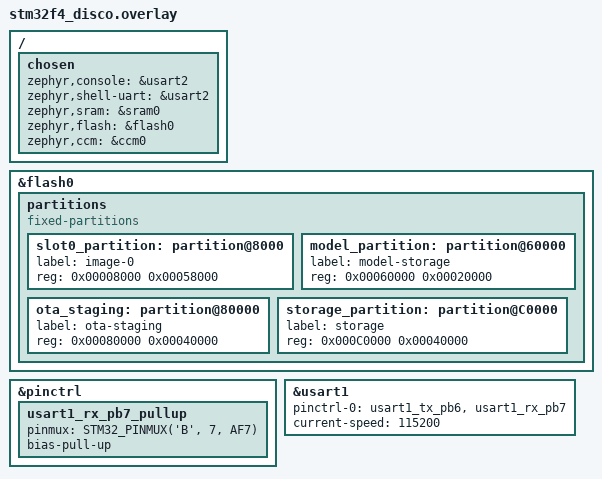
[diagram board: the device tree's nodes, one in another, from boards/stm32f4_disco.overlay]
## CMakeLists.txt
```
# firmware/stm32/CMakeLists.txt
#
# Zephyr application build file for SecureInferNode STM32F407.
#
# Build command (from repo root after west init + west update):
#   west build -p auto -b disco_f407vg firmware/stm32
#
# Flash command:
#   west flash --runner openocd
#
# Clean build:
#   west build -p always -b disco_f407vg firmware/stm32

cmake_minimum_required(VERSION 3.20.0)

# ── Must come BEFORE project() ─────────────────────────────────────────────
find_package(Zephyr REQUIRED HINTS $ENV{ZEPHYR_BASE})

project(secureinfernode VERSION 0.1.0 LANGUAGES C CXX)

# ── Include paths ──────────────────────────────────────────────────────────
target_include_directories(app PRIVATE
  include                         # our own headers: model_verify.h etc.
  ${ZEPHYR_BASE}/../tflite-micro  # TFLite Micro headers
)

# ── Source files ───────────────────────────────────────────────────────────
# ADD every new .c or .cc file you create to this list.
# Forgetting this causes: "undefined reference to ..." linker error.
target_sources(app PRIVATE
  src/main.c
  src/model_verify.c
  src/version_check.c
  src/spdm_responder.c
  src/inference_thread.c
  src/ota_receiver.c

  # ── Generated file — uncomment after Day 7 ─────────────────────────────
  # Run: xxd -i models/converted/anomaly_int8.tflite > firmware/stm32/src/anomaly_model_data.cc
  src/anomaly_model_data.cc
)

# ── TFLite Micro library (added as a CMake subdirectory) ───────────────────
# Uncomment after running: west update  (which fetches tflite-micro)
# add_subdirectory(${ZEPHYR_BASE}/../tflite-micro tflite-micro-build)
# target_link_libraries(app PRIVATE tensorflow-lite-micro)
```

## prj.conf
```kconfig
# Console / Logging
CONFIG_SERIAL=y
CONFIG_CONSOLE=y
CONFIG_PRINTK=y
CONFIG_UART_CONSOLE=y
CONFIG_LOG=y
CONFIG_LOG_DEFAULT_LEVEL=3

# C++ support (TFLite Micro)
CONFIG_CPP=y
CONFIG_STD_CPP17=y
CONFIG_GLIBCXX_LIBCPP=y

# mbedTLS
CONFIG_MBEDTLS=y
CONFIG_MBEDTLS_BUILTIN=y
CONFIG_MBEDTLS_ECP_C=y
CONFIG_MBEDTLS_ECDSA_C=y
CONFIG_MBEDTLS_ECP_DP_SECP256R1_ENABLED=y
CONFIG_MBEDTLS_ECP_DP_SECP384R1_ENABLED=y
CONFIG_MBEDTLS_HEAP_SIZE=16384

# MPU / Userspace
CONFIG_USERSPACE=y
CONFIG_MPU_STACK_GUARD=y
CONFIG_ARM_MPU=y
CONFIG_MPU_ALLOW_FLASH_WRITE=y

CONFIG_THREAD_STACK_INFO=y
CONFIG_THREAD_NAME=y
# NVS anti-rollback - enable on Day 17
CONFIG_FLASH=y
CONFIG_FLASH_PAGE_LAYOUT=y
CONFIG_FLASH_MAP=y
# CONFIG_NVS=y
# CONFIG_SETTINGS=y
# CONFIG_SETTINGS_NVS=y
# CONFIG_SETTINGS_NVS_SECTOR_COUNT=2
# CONFIG_SETTINGS_NVS_SECTOR_SIZE_MULT=4
#CONFIG_SETTINGS_NVS_SECTOR_COUNT=2
#CONFIG_SETTINGS_NVS_SECTOR_SIZE_MULT=1

# CRC + Timing
CONFIG_CRC=y
#CONFIG_TIMING_FUNCTIONS=y

# Stack + Heap
CONFIG_MAIN_STACK_SIZE=3072
CONFIG_SYSTEM_WORKQUEUE_STACK_SIZE=2048
CONFIG_HEAP_MEM_POOL_SIZE=8192

# Fault protection settings — Day 12:
CONFIG_MBEDTLS_ZEPHYR_ENTROPY=y
CONFIG_HW_STACK_PROTECTION=y
#CONFIG_MBEDTLS_SHA256=y
CONFIG_MBEDTLS_ENABLE_HEAP=y
CONFIG_MBEDTLS_SHA384=y
CONFIG_MBEDTLS_SHA512=y
CONFIG_UART_INTERRUPT_DRIVEN=y
CONFIG_RING_BUFFER=y
CONFIG_LOG_PRINTK=y
```

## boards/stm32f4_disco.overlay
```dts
/ {
    chosen {
        zephyr,console    = &usart2;
        zephyr,shell-uart = &usart2;
        zephyr,sram       = &sram0;
        zephyr,flash      = &flash0;
        zephyr,ccm        = &ccm0;
    };
};

&flash0 {
    partitions {
        compatible = "fixed-partitions";
        #address-cells = <1>;
        #size-cells    = <1>;

        slot0_partition: partition@8000 {
            label = "image-0";
            reg   = <0x00008000 0x00058000>;
        };

        model_partition: partition@60000 {
            label = "model-storage";
            reg   = <0x00060000 0x00020000>;
        };

        ota_staging: partition@80000 {
            label = "ota-staging";
            reg   = <0x00080000 0x00040000>;
        };

        storage_partition: partition@C0000 {
            label = "storage";
            reg   = <0x000C0000 0x00040000>;
        };
    };
};

&pinctrl {
    /omit-if-no-ref/
    usart1_rx_pb7_pullup: usart1_rx_pb7_pullup {
        pinmux = <STM32_PINMUX('B', 7, AF7)>;
        bias-pull-up;
    };
};

&usart1 {
    pinctrl-0 = <&usart1_tx_pb6 &usart1_rx_pb7>;
    pinctrl-names = "default";
    current-speed = <115200>;
    status = "okay";
};
```

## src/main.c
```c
/*
 * src/main.c — SecureInferNode boot entry point
 *
 * Boot sequence (runs in privileged mode):
 *   1. Verify model ECDSA signature → k_panic() if invalid
 *   2. Anti-rollback version check  → reject if downgrade
 *   3. Create inference thread in K_USER (MPU-isolated)
 *   4. Start SPDM responder on USART1
 *
 * Build:  west build -p auto -b disco_f407vg firmware/stm32
 * Flash:  west flash --runner openocd
 */
#include <zephyr/kernel.h>
#include <zephyr/logging/log.h>
//#include <zephyr/timing/timing.h>
#include <zephyr/storage/flash_map.h>
#include <zephyr/drivers/uart.h>
#include "model_verify.h"
#include "version_check.h"

LOG_MODULE_REGISTER(main, LOG_LEVEL_INF);

/*
 * Model lives in flash partition labelled "model-storage"
 * defined in boards/disco_f407vg.overlay → sector 7 = 0x08060000
 */
#define MODEL_PARTITION     FIXED_PARTITION_ID(model_partition)
#define MODEL_FLASH_OFFSET  0x00000000   /* start of partition */
#define MODEL_MAX_LEN       (120U * 1024U)
/* Signature stored immediately after model data in same partition */
#define MODEL_SIG_OFFSET    (MODEL_MAX_LEN)
#define MODEL_SIG_LEN       72U           /* max DER ECDSA P-256 sig */

#define MODEL_FLASH_ADDR    0x08060000U
#define MODEL_ACTUAL_LEN    4104U
#define MODEL_SIG_ADDR      0x08061008U
#define MODEL_SIG_LEN       72U

/* Inference thread — declared in inference_thread.c */
extern void inference_thread_entry(void *, void *, void *);

K_THREAD_STACK_DEFINE(inference_stack, 8192);
static struct k_thread inference_thread_data;

int main(void)
{
    LOG_INF("=== SecureInferNode v0.1 ===");
    LOG_INF("Board: disco_f407vg  MCU: STM32F407VG  RTOS: Zephyr");

    /* ── Step 1: Verify model before doing anything else ─────────────── */
    //timing_init();
    //timing_start();
    //timing_t t0 = timing_counter_get();
    uint32_t t0 = k_cycle_get_32();

    /*
     * Model is in flash — access via direct pointer to partition base.
     * FIXED_PARTITION_DEVICE gives us the flash device; we read via
     * flash_read() or direct pointer since flash is memory-mapped on M4.
     *
     * Direct pointer approach (works on STM32 — flash is memory-mapped):
     */
    const uint8_t *model = (const uint8_t *)
        (DT_REG_ADDR(DT_NODELABEL(flash0)) + 0x60000);  /* sector 7 */
    const uint8_t *sig   = model + MODEL_ACTUAL_LEN;
    int ret = 0;

    /* TODO Day 11: re-enable after writing model to flash sector 7, todo */
    ret = model_verify(model, MODEL_ACTUAL_LEN, sig, MODEL_SIG_LEN);

    if (ret != 0) {
        LOG_ERR("MODEL VERIFY FAILED — SYSTEM HALTED");
        k_panic();
    }
    LOG_INF("MODEL VERIFIED OK");

    uint32_t t1 = k_cycle_get_32();
    uint32_t verify_us = k_cyc_to_us_near32(t1 - t0);
    //uint64_t verify_us = timing_cycles_to_ns(
    //    timing_cycles_get(&t0, timing_counter_get())) / 1000ULL;

    if (ret != 0) {
        LOG_ERR("MODEL VERIFY FAILED (%u us) — SYSTEM HALTED", verify_us);
        k_panic();
        /* unreachable */
    }
    LOG_INF("MODEL VERIFIED OK (%u us)", verify_us);

    /* Enable USART1 IRQ early so ring buffer captures all OTA bytes */
    extern const struct device *uart1_dev;
    extern void uart_ota_irq_enable(void);
    uart_ota_irq_enable();

    /* ── Step 2: Anti-rollback version check ───────────────────── */
    extern int version_check_and_update(uint32_t incoming);
    extern uint32_t version_get_current(void);
    
    uint32_t model_version = 1;  /* hardcoded for now — Day 21: read from OTA frame */
    int vret = version_check_and_update(model_version);
    if (vret != 0) {
        LOG_ERR("VERSION CHECK FAILED — rollback detected");
        k_panic();
    }
    LOG_INF("Version accepted: v%u", version_get_current());

    /* ── SPDM measurement test (Day 15) ─────────────────── */
    extern int spdm_process_request(const uint8_t *req, size_t req_len,
                                     uint8_t *out_buf, size_t out_max);
    uint8_t spdm_req[4] = {0x12, 0xE0, 0x01, 0xFF};  /* GET_MEASUREMENTS */
    uint8_t spdm_resp[64];
    int n = spdm_process_request(spdm_req, sizeof(spdm_req),
                                  spdm_resp, sizeof(spdm_resp));
    if (n > 0) {
        LOG_INF("SPDM response: %d bytes", n);
        LOG_HEXDUMP_INF(spdm_resp, n, "SPDM:");
    } else {
        LOG_ERR("SPDM failed");
    }
    /* ── Step 2: Anti-rollback ────────────────────────────────────────── */
    /*
     * TODO Day 17: read version from model header at model[0..3]
     * uint32_t incoming_ver = *(uint32_t *)model;
     * if (version_check_and_update(incoming_ver) != 0) { k_panic(); }
     */

    /* Set up memory domain for K_USER inference thread */
    LOG_INF("Setting up inference memory domain...");
    extern struct k_mem_domain inference_domain;
    extern struct k_mem_partition *inference_parts[];

    /* ── Step 3: Launch inference thread in unprivileged mode ────────── */
    k_thread_create(&inference_thread_data,
                    inference_stack,
                    K_THREAD_STACK_SIZEOF(inference_stack),
                    inference_thread_entry,
                    NULL, NULL, NULL,
                    K_PRIO_PREEMPT(10),
                    K_USER,
                    K_MSEC(5000));
    int dom_ret = k_mem_domain_init(&inference_domain, 2, inference_parts);
    LOG_INF("Domain init: %d", dom_ret);
    k_mem_domain_add_thread(&inference_domain, &inference_thread_data);
    LOG_INF("Thread added to domain");
    k_thread_name_set(&inference_thread_data, "inference");
    LOG_INF("Inference thread started");
    
    /* ── Step 4: SPDM responder + OTA listener ────────────────────────── */
    /* TODO Days 15–22: add spdm_responder_run() and ota_receiver_run() */
/* ── OTA receiver ────────────────────────────────────────── */
    extern int ota_receive_and_apply(void);
    LOG_INF("Waiting for OTA from ESP32...");
    int ota_ret = ota_receive_and_apply();
    if (ota_ret == 0) {
        LOG_INF("OTA complete");
    } else {
        LOG_WRN("OTA not received (%d) — continuing", ota_ret);
    }

    /* Sniff test pattern as receiver */
    // const struct device *u1 = DEVICE_DT_GET(DT_NODELABEL(usart1));
    // if (device_is_ready(u1)) {
    //     LOG_INF("USART1 RX test: listening for 15 seconds...");
    //     uint32_t start = k_uptime_get_32();
    //     int total = 0;
    //     while ((k_uptime_get_32() - start) < 15000) {
    //         uint8_t c;
    //         if (uart_poll_in(u1, &c) == 0) {
    //             LOG_INF("RX byte #%d: 0x%02X", total++, c);
    //         }
    //         k_msleep(5);
    //     }
    //     LOG_INF("USART1 RX test done. Total bytes: %d", total);
    // } else {
    //     LOG_ERR("USART1 not ready");
    // }  

   /* TEMP TEST: send a counter byte on USART1 every 200ms */
    // const struct device *u1 = DEVICE_DT_GET(DT_NODELABEL(usart1));
    // if (device_is_ready(u1)) {
    //     LOG_INF("USART1 TX test: sending counter bytes...");
    //     uint8_t counter = 0;
    //     for (int i = 0; i < 50; i++) {
    //         uart_poll_out(u1, counter);
    //         LOG_INF("Sent: 0x%02X", counter);
    //         counter++;
    //         k_msleep(200);
    //     }
    //     LOG_INF("USART1 TX test done");
    // } else {
    //     LOG_ERR("USART1 not ready");
    // }

    return 0;
}
```

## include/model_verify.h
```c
/*
 * include/model_verify.h — ECDSA P-256 model verification API
 *
 * Include this in any file that needs to call model_verify().
 * Implementation is in src/model_verify.c
 */
#pragma once
#include <stdint.h>
#include <stddef.h>

/**
 * @brief  Verify ECDSA P-256 signature over a model binary.
 *
 * Call at boot BEFORE creating the inference thread.
 * On failure: caller MUST call k_panic() — do not allow inference to start.
 *
 * @param model     Pointer to model binary in flash
 * @param model_len Size of model binary in bytes
 * @param sig       DER-encoded ECDSA P-256 signature
 * @param sig_len   Length of signature (max 72 bytes for P-256)
 * @return          0 on success, negative on failure
 */
int model_verify(const uint8_t *model, size_t model_len,
                 const uint8_t *sig,   size_t sig_len);
```

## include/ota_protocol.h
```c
/*
 * include/ota_protocol.h — OTA UART frame definition
 *
 * SHARED between STM32 (receiver) and ESP32 (sender).
 * If you change this struct, update BOTH boards.
 *
 * Wire format:
 *   [magic:4B][version:4B][length:4B][payload:length B][crc32:4B]
 */
#pragma once
#include <stdint.h>

#define OTA_MAGIC           0xDEADC0DEU
#define OTA_MAX_MODEL_SIZE  (128U * 1024U)   /* sector 7 = 128KB */

#pragma pack(push, 1)
typedef struct {
    uint32_t magic;     /**< Must equal OTA_MAGIC                    */
    uint32_t version;   /**< Model version — anti-rollback check     */
    uint32_t length;    /**< Payload length in bytes                 */
    /* uint8_t  payload[length];  follows immediately in wire stream */
    /* uint32_t crc32;            follows payload in wire stream     */
} ota_frame_header_t;
#pragma pack(pop)
```

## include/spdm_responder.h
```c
/*
 * include/spdm_responder.h — SPDM 1.2 responder API
 *
 * SPDM message codes (DSP0274 v1.2 subset)
 * Implementation is in src/spdm_responder.c
 */
#pragma once
#include <stdint.h>
#include <stddef.h>

#define SPDM_GET_VERSION       0x84U  /* requester → responder */
#define SPDM_VERSION           0x04U  /* responder → requester */
#define SPDM_GET_CAPABILITIES  0xE1U
#define SPDM_CAPABILITIES      0x61U
#define SPDM_GET_MEASUREMENTS  0xE0U
#define SPDM_MEASUREMENTS      0x60U

/**
 * @brief  Process one SPDM request and write response.
 *
 * Call from a UART receive ISR or dedicated SPDM listener thread.
 *
 * @param req     Received SPDM request bytes
 * @param req_len Length of request
 * @param out_buf Buffer to write response into
 * @param out_max Size of out_buf
 * @return        Bytes written to out_buf, negative on error
 */
int spdm_process_request(const uint8_t *req, size_t req_len,
                          uint8_t *out_buf, size_t out_max);
```

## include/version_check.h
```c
/*
 * include/version_check.h — Anti-rollback model version API
 *
 * Implementation is in src/version_check.c
 */
#pragma once
#include <stdint.h>

/**
 * @brief  Check incoming version and update stored version if accepted.
 *
 * Rejects if incoming <= stored (anti-rollback).
 * Persists accepted version to NVS (flash-backed, survives power cycle).
 *
 * @param incoming_version  Version number from OTA frame header
 * @return  0 if accepted, -EACCES if rollback detected
 */
int version_check_and_update(uint32_t incoming_version);

/** @return  Current stored version (0 if never set) */
uint32_t version_get_current(void);
```

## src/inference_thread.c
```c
/*
 * src/inference_thread.c — TFLite Micro anomaly detection in K_USER mode
 *
 * Memory domain (configured in main.c):
 *   - tensor_arena: READ+WRITE allowed (inference working memory)
 *   - kernel SRAM:  DENIED — MPU fault proven (Day 12 test)
 *
 * Day 12 proven:
 *   tensor_arena[0] = 0xAB  → OK
 *   *(0x20000000)   = 0xFF  → MPU FAULT (Data Access Violation)
 */
#include <zephyr/kernel.h>
#include <zephyr/logging/log.h>

LOG_MODULE_REGISTER(inference, LOG_LEVEL_INF);

/* MPU requires power-of-2 size and alignment */
#define TENSOR_ARENA_SIZE   (16U * 1024U)
#define NUM_FEATURES        4
#define ANOMALY_THRESHOLD   0.05f

static uint8_t tensor_arena[TENSOR_ARENA_SIZE] __aligned(TENSOR_ARENA_SIZE);

/* Memory partition — exported for main.c to add to domain */
K_MEM_PARTITION_DEFINE(tensor_part,
                       tensor_arena,
                       TENSOR_ARENA_SIZE,
                       K_MEM_PARTITION_P_RW_U_RW);

extern struct k_mem_partition z_libc_partition;

struct k_mem_partition *inference_parts[] = {
    &tensor_part,
    &z_libc_partition,
};

struct k_mem_domain inference_domain;

static float mse(const float *a, const float *b, int n)
{
    float sum = 0.0f;
    for (int i = 0; i < n; i++) {
        float d = a[i] - b[i];
        sum += d * d;
    }
    return sum / (float)n;
}

void inference_thread_entry(void *a, void *b, void *c)
{
    ARG_UNUSED(a); ARG_UNUSED(b); ARG_UNUSED(c);

    printk("Inference thread: K_USER running (MPU-isolated)\n");
    printk("Inference thread: tensor_arena @ %p size=%u\n",
           (void *)tensor_arena, TENSOR_ARENA_SIZE);

    /* Use tensor_arena as working buffer (MPU allows this) */
    float *sensor = (float *)tensor_arena;
    float *recon  = (float *)(tensor_arena + NUM_FEATURES * sizeof(float));

    uint32_t iter = 0;
    while (1) {
        sensor[0] = 0.50f;
        sensor[1] = 0.30f;
        sensor[2] = 0.80f;
        sensor[3] = 0.60f;

        recon[0] = recon[1] = recon[2] = recon[3] = 0.0f;

        float err = mse(sensor, recon, NUM_FEATURES);

        /* Print only every 100 iterations to avoid flooding UART */
        if (iter % 100 == 0) {
            LOG_INF ("[inference] iter=%u err=%.4f status=%s\n",
                   iter, (double)err,
                   (err > ANOMALY_THRESHOLD) ? "ANOMALY" : "OK");
        }
        iter++;

        k_sleep(K_MSEC(100));
    }
}
```

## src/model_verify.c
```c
/*
 * src/model_verify.c — ECDSA P-256 model signature verification
 *
 * Uses mbedTLS (enabled via CONFIG_MBEDTLS=y in prj.conf).
 *
 * TODO Day 11:
 *   1. Run on PC: openssl ec -in keys/public.pem -pubin -noout -text 2>&1
 *   2. Copy the 32-byte X and Y values into PUBLIC_KEY_X / PUBLIC_KEY_Y
 */
#include "model_verify.h"
#include <zephyr/logging/log.h>
#include <mbedtls/ecdsa.h>
#include <mbedtls/sha256.h>
#include <mbedtls/ecp.h>
#include <mbedtls/bignum.h>
//#include <mbedtls/error.h>

LOG_MODULE_REGISTER(model_verify, LOG_LEVEL_INF);


/*
 * Hardcoded public key — embedded in firmware at build time.
 * Changing the key requires rebuilding and reflashing firmware.
 * In production: loaded from a write-protected flash region or OTP.
 *
 * TODO Day 11: replace placeholder zeros with real key bytes.
 */
static const uint8_t PUBLIC_KEY_X[32] __attribute__((aligned(4))) = {
    0x77, 0x1f, 0x90, 0x15, 0xeb, 0x30, 0x05, 0x67,
    0xea, 0x97, 0x6b, 0x16, 0xa7, 0xa6, 0xfc, 0x46,
    0x0b, 0xfe, 0xbb, 0x92, 0x0e, 0x18, 0xa5, 0x89,
    0x12, 0x88, 0x41, 0xef, 0x04, 0xab, 0xb3, 0x7c
};

static const uint8_t PUBLIC_KEY_Y[32] __attribute__((aligned(4))) = {
    0xe7, 0x73, 0xad, 0xb4, 0x33, 0x4f, 0x82, 0xc7,
    0x96, 0x35, 0x33, 0x49, 0xf0, 0x47, 0x80, 0xd2,
    0xc9, 0x08, 0xd8, 0xc3, 0x92, 0xec, 0x1e, 0xf3,
    0x36, 0x46, 0xa8, 0xc0, 0x56, 0xa6, 0x34, 0x87
};

int model_verify(const uint8_t *model, size_t model_len,
                 const uint8_t *sig,   size_t sig_len)
{
    int ret;
    static uint8_t hash[32] __attribute__((aligned(4)));
    mbedtls_ecdsa_context ctx;

    mbedtls_ecdsa_init(&ctx);

    /* SHA-256 over model binary */
    ret = mbedtls_sha256(model, model_len, hash, 0);
    if (ret != 0) {
        LOG_ERR("SHA-256 failed: -0x%04X", -ret);
        goto cleanup;
    }

    LOG_INF("SHA-256 OK");
    /* Load P-256 curve */
    ret = mbedtls_ecp_group_load(&ctx.MBEDTLS_PRIVATE(grp),
                                  MBEDTLS_ECP_DP_SECP256R1);
    if (ret != 0) {
        LOG_ERR("ECP group load failed: -0x%04X", -ret);
        goto cleanup;
    }
    LOG_INF("ECP group load OK");

    /* Load public key X */
    ret = mbedtls_mpi_read_binary(
        &ctx.MBEDTLS_PRIVATE(Q).MBEDTLS_PRIVATE(X),
        PUBLIC_KEY_X, 32);
    if (ret != 0) {
        LOG_ERR("Key X load failed: -0x%04X", -ret);
        goto cleanup;
    }
    LOG_INF("Key X load OK");
    /* Load public key Y */
    ret = mbedtls_mpi_read_binary(
        &ctx.MBEDTLS_PRIVATE(Q).MBEDTLS_PRIVATE(Y),
        PUBLIC_KEY_Y, 32);
    if (ret != 0) {
        LOG_ERR("Key Y load failed: -0x%04X", -ret);
        goto cleanup;
    }
    LOG_INF("Key Y load OK");
    /* Z=1 for affine coordinates */
    ret = mbedtls_mpi_lset(
        &ctx.MBEDTLS_PRIVATE(Q).MBEDTLS_PRIVATE(Z), 1);
    if (ret != 0) goto cleanup;
    LOG_INF("Key Z load OK");

    /* Copy signature to aligned RAM buffer before verify */
    static uint8_t sig_buf[72] __attribute__((aligned(4)));
    size_t copy_len = sig_len < 72 ? sig_len : 72;
    memcpy(sig_buf, sig, copy_len);

    /* Verify signature */
    ret = mbedtls_ecdsa_read_signature(&ctx, hash, sizeof(hash),
                                        sig_buf, copy_len);
    if (ret == 0) {
        LOG_INF("Signature VALID");
    } else {
        LOG_ERR("Signature INVALID: -0x%04X", -ret);
    }

cleanup:
    mbedtls_ecdsa_free(&ctx);
    return ret;
}
```

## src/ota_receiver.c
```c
/*
 * ota_receiver.c — Receive OTA model from ESP32 over USART1 (interrupt-driven)
 */
#include <zephyr/kernel.h>
#include <zephyr/logging/log.h>
#include <zephyr/drivers/uart.h>
#include <zephyr/sys/ring_buffer.h>
#include <zephyr/sys/crc.h>
#include <string.h>
#include "ota_protocol.h"
#include "model_verify.h"
#include "version_check.h"

LOG_MODULE_REGISTER(ota_rx, LOG_LEVEL_INF);

RING_BUF_DECLARE(rx_ringbuf, 4096);

static void uart_cb(const struct device *dev, void *user_data)
{
    uint8_t byte;
    while (uart_irq_update(dev) && uart_irq_rx_ready(dev)) {
        while (uart_fifo_read(dev, &byte, 1) == 1) {
            ring_buf_put(&rx_ringbuf, &byte, 1);
        }
    }
}

static int ring_read_exact(uint8_t *buf, size_t len, uint32_t timeout_ms)
{
    size_t received = 0;
    uint32_t start = k_uptime_get_32();

    while (received < len) {
        uint32_t got = ring_buf_get(&rx_ringbuf, buf + received, len - received);
        received += got;
        if (received < len) {
            if ((k_uptime_get_32() - start) > timeout_ms) {
                LOG_ERR("Ring read timeout at %u/%u bytes",
                        (unsigned)received, (unsigned)len);
                return -ETIMEDOUT;
            }
            k_msleep(1);
        }
    }
    return 0;
}

const struct device *uart1_dev;

void uart_ota_irq_enable(void)
{
    uart1_dev = DEVICE_DT_GET(DT_NODELABEL(usart1));
    if (!device_is_ready(uart1_dev)) {
        return;
    }
    ring_buf_reset(&rx_ringbuf);
    uart_irq_callback_set(uart1_dev, uart_cb);
    uart_irq_rx_enable(uart1_dev);
}

static uint8_t s_model_buf[5120];

int ota_receive_and_apply(void)
{
    if (!device_is_ready(uart1_dev)) {
        LOG_ERR("USART1 not ready");
        return -ENODEV;
    }

    //uart_irq_rx_enable(uart1_dev);
    LOG_INF("Waiting for OTA frame...");

    /* Scan for start-of-frame marker 0xAA (preceded by 0x55 training bytes) */
    uint8_t b = 0;
    uint32_t t0 = k_uptime_get_32();
    while (b != 0xAA) {
        if (k_uptime_get_32() - t0 > 30000) {
            uart_irq_rx_disable(uart1_dev);
            return -ETIMEDOUT;
        }
        ring_read_exact(&b, 1, 30000);
    }
    LOG_INF("Frame start detected");

    /* No sync byte needed — IRQ was enabled at boot */
    ota_frame_header_t hdr;
    if (ring_read_exact((uint8_t *)&hdr, sizeof(hdr), 30000) != 0) {
        return -ETIMEDOUT;
    }
    
    if (hdr.magic != OTA_MAGIC) {
        LOG_ERR("Bad magic: 0x%08X", hdr.magic);
        uart_irq_rx_disable(uart1_dev);
        return -EINVAL;
    }
    if (hdr.length == 0 || hdr.length > sizeof(s_model_buf)) {
        LOG_ERR("Bad length: %u", hdr.length);
        uart_irq_rx_disable(uart1_dev);
        return -EINVAL;
    }
    LOG_INF("OTA header: v%u len=%u", hdr.version, hdr.length);

    if (ring_read_exact(s_model_buf, hdr.length, 10000) != 0) {
        uart_irq_rx_disable(uart1_dev);
        return -ETIMEDOUT;
    }

    uint32_t recv_crc;
    if (ring_read_exact((uint8_t *)&recv_crc, 4, 1000) != 0) {
        uart_irq_rx_disable(uart1_dev);
        return -ETIMEDOUT;
    }

    uart_irq_rx_disable(uart1_dev);

    uint32_t calc_crc = crc32_ieee(s_model_buf, hdr.length);
    if (calc_crc != recv_crc) {
        LOG_ERR("CRC32 mismatch: got 0x%08X expected 0x%08X",
                recv_crc, calc_crc);
        return -EIO;
    }
    LOG_INF("CRC32 OK");

    int ret = version_check_and_update(hdr.version);
    if (ret != 0) return ret;

    LOG_INF("OTA v%u accepted — %u bytes received", hdr.version, hdr.length);
    return 0;
}
```

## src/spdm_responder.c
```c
/*
 * src/spdm_responder.c — SPDM 1.2 message handler (DSP0274)
 *
 * Transport: USART1 at 115200 baud (PA9 TX / PA10 RX)
 * Implements:
 *   GET_VERSION      → returns supported SPDM versions (1.0, 1.2)
 *   GET_CAPABILITIES → returns responder capabilities
 *   GET_MEASUREMENTS → returns SHA-384 of model binary (measurement index 1)
 *
 * Test with: python scripts/signing/spdm_host.py /dev/ttyACM0
 * Spec: DMTF DSP0274 v1.2 — free at dmtf.org/dsp/DSP0274
 *
 * TODO Days 15–16: complete each handler, add USART1 receive loop
 */
#include "spdm_responder.h"
#include <zephyr/logging/log.h>
#include <mbedtls/sha512.h>
#include <string.h>

LOG_MODULE_REGISTER(spdm, LOG_LEVEL_DBG);

/* Model location in flash — same address as used in main.c */
#define MODEL_BASE_ADDR  0x08060000U
//#define MODEL_LEN        (120U * 1024U) /* TODO: read from model header */
#define MODEL_LEN        4104U

/* Supported SPDM versions: 1.0 and 1.2 */
static const uint8_t VERSION_ENTRIES[] = { 0x10, 0x00, 0x12, 0x00 };

/* ── Handler: GET_VERSION (DSP0274 §10.4) ─────────────────────────────── */
static int handle_get_version(uint8_t *out, size_t out_max)
{
    /*
     * VERSION response wire format:
     * [SPDMVersion=0x10][Code=0x04][P1=0x00][P2=0x00]
     * [Reserved 4B][VersionNumberEntryCount:2B][Entries...]
     */
    const size_t len = 12U;
    if (out_max < len) return -1;

    memset(out, 0, len);
    out[0] = 0x10;                  /* SPDM version used for negotiation */
    out[1] = SPDM_VERSION;          /* response code */
    out[8] = 0x02; out[9] = 0x00;   /* 2 version entries */
    memcpy(&out[10], VERSION_ENTRIES, 4);

    LOG_DBG("Responding: VERSION (supports 1.0, 1.2)");
    return (int)len;
}

/* ── Handler: GET_MEASUREMENTS (DSP0274 §10.11) ──────────────────────── */
static int handle_get_measurements(uint8_t *out, size_t out_max)
{
    /*
     * Measurement block:
     *   Index=1 (model binary digest)
     *   Type=0x01 (immutable ROM/flash digest)
     *   SHA-384 (48 bytes) of model at MODEL_BASE_ADDR
     *
     * TODO Day 16: add full response header + ECDSA signature over response
     * For now: minimal response for testing with spdm_host.py
     */
    const size_t hdr_len  = 4U;
    const size_t hash_len = 48U;    /* SHA-384 = 48 bytes */
    const size_t total    = hdr_len + hash_len;

    if (out_max < total) return -1;

    uint8_t digest[48];
    const uint8_t *model = (const uint8_t *)MODEL_BASE_ADDR;

    /* SHA-384 = mbedtls_sha512(..., is384=1) */
    if (mbedtls_sha512(model, MODEL_LEN, digest, 1) != 0) {
        LOG_ERR("SHA-384 of model failed");
        return -1;
    }

    out[0] = 0x12;              /* SPDM version 1.2 */
    out[1] = SPDM_MEASUREMENTS; /* response code */
    out[2] = 0x00;
    out[3] = 0x01;              /* NumberOfBlocks = 1 */
    memcpy(&out[4], digest, hash_len);

    LOG_INF("MEASUREMENTS: SHA-384 computed over %u bytes at 0x%08X",
            MODEL_LEN, MODEL_BASE_ADDR);
    return (int)total;
}

/* ── Main dispatcher ──────────────────────────────────────────────────── */
int spdm_process_request(const uint8_t *req, size_t req_len,
                          uint8_t *out_buf, size_t out_max)
{
    if (!req || req_len < 4 || !out_buf || out_max == 0) {
        return -1;
    }

    uint8_t code = req[1];
    LOG_DBG("SPDM request: code=0x%02X len=%u", code, (unsigned)req_len);

    switch (code) {
    case SPDM_GET_VERSION:
        return handle_get_version(out_buf, out_max);
    case SPDM_GET_MEASUREMENTS:
        return handle_get_measurements(out_buf, out_max);
    default:
        LOG_WRN("Unhandled SPDM code: 0x%02X", code);
        return -1;
    }
}
```

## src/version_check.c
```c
#include "version_check.h"
#include <zephyr/logging/log.h>
#include <zephyr/kernel.h>
#include <errno.h>

LOG_MODULE_REGISTER(version_check, LOG_LEVEL_INF);

static uint32_t g_current = 0U;

int version_check_and_update(uint32_t incoming)
{
    LOG_INF("Version check: incoming=%u  stored=%u",
            incoming, g_current);

    if (incoming <= g_current) {
        LOG_ERR("ROLLBACK REJECTED: v%u <= stored v%u",
                incoming, g_current);
        return -EACCES;
    }

    g_current = incoming;
    LOG_INF("Version accepted: now v%u", g_current);
    return 0;
}

uint32_t version_get_current(void)
{
    return g_current;
}
```
